# M46B register map
File version: 2.0.2.2
Registers are 32-bit, read-write, reset 0x0 unless marked. A register's access mark holds for its fields unless they carry their own. Offsets are from the block's base; [hi:lo] are bit positions; {n}, {i} and the like mark numbered series.

## MLA — Multiple Length Arithmetic Coprocessor (MLA)
Base 0x400B9000
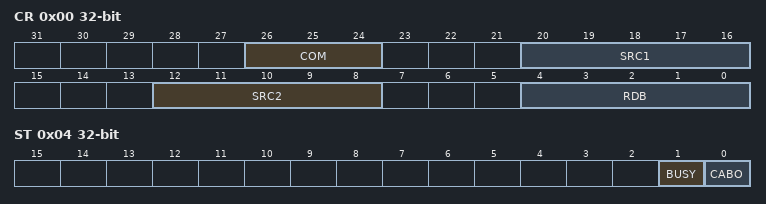
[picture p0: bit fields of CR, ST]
0x00 CR reset not defined — Control Register
  [26:24] COM, [20:16] SRC1, [12:8] SRC2, [4:0] RDB
0x04 ST — Status Register
  [1] BUSY, [0] CABO
0x0C PARA reset not defined — Montgomery Parameter Register
{0x10+4i} BLK1_{i} reset not defined (i=0..7) — General-purpose Register Block 1 (bit {32i+31} - {32i})
  [31:0] BLK
{0x30+4i} BLK2_{i} reset not defined (i=0..7) — General-purpose Register Block 2 (bit {32i+31} - {32i})
  [31:0] BLK
{0x50+4i} BLK3_{i} reset not defined (i=0..7) — General-purpose Register Block 3 (bit {32i+31} - {32i})
  [31:0] BLK
{0x70+4i} BLK4_{i} reset not defined (i=0..7) — General-purpose Register Block 4 (bit {32i+31} - {32i})
  [31:0] BLK
{0x90+4i} BLK5_{i} reset not defined (i=0..7) — General-purpose Register Block 5 (bit {32i+31} - {32i})
  [31:0] BLK
{0xB0+4i} BLK6_{i} reset not defined (i=0..7) — General-purpose Register Block 6 (bit {32i+31} - {32i})
  [31:0] BLK
{0xD0+4i} BLK7_{i} reset not defined (i=0..7) — General-purpose Register Block 7 (bit {32i+31} - {32i})
  [31:0] BLK
{0xF0+4i} BLK8_{i} reset not defined (i=0..7) — General-purpose Register Block 8 (bit {32i+31} - {32i})
  [31:0] BLK
{0x110+4i} BLK9_{i} reset not defined (i=0..7) — General-purpose Register Block 9 (bit {32i+31} - {32i})
  [31:0] BLK
{0x130+4i} BLK10_{i} reset not defined (i=0..7) — General-purpose Register Block 10 (bit {32i+31} - {32i})
  [31:0] BLK
{0x150+4i} BLK11_{i} reset not defined (i=0..7) — General-purpose Register Block 11 (bit {32i+31} - {32i})
  [31:0] BLK
{0x170+4i} BLK12_{i} reset not defined (i=0..7) — General-purpose Register Block 12 (bit {32i+31} - {32i})
  [31:0] BLK
{0x190+4i} BLK13_{i} reset not defined (i=0..7) — General-purpose Register Block 13 (bit {32i+31} - {32i})
  [31:0] BLK
{0x1B0+4i} BLK14_{i} reset not defined (i=0..7) — General-purpose Register Block 14 (bit {32i+31} - {32i})
  [31:0] BLK
{0x1D0+4i} BLK15_{i} reset not defined (i=0..7) — General-purpose Register Block 15 (bit {32i+31} - {32i})
  [31:0] BLK
{0x1F0+4i} BLK16_{i} reset not defined (i=0..7) — General-purpose Register Block 16 (bit {32i+31} - {32i})
  [31:0] BLK
{0x210+4i} BLK17_{i} reset not defined (i=0..7) — General-purpose Register Block 17 (bit {32i+31} - {32i})
  [31:0] BLK
{0x230+4i} BLK18_{i} reset not defined (i=0..7) — General-purpose Register Block 18 (bit {32i+31} - {32i})
  [31:0] BLK
{0x250+4i} BLK19_{i} reset not defined (i=0..7) — General-purpose Register Block 19 (bit {32i+31} - {32i})
  [31:0] BLK
{0x270+4i} BLK20_{i} reset not defined (i=0..7) — General-purpose Register Block 20 (bit {32i+31} - {32i})
  [31:0] BLK
{0x290+4i} BLK21_{i} reset not defined (i=0..7) — General-purpose Register Block 21 (bit {32i+31} - {32i})
  [31:0] BLK
{0x2B0+4i} BLK22_{i} reset not defined (i=0..7) — General-purpose Register Block 22 (bit {32i+31} - {32i})
  [31:0] BLK
{0x2D0+4i} BLK23_{i} reset not defined (i=0..7) — General-purpose Register Block 23 (bit {32i+31} - {32i})
  [31:0] BLK
{0x2F0+4i} BLK24_{i} reset not defined (i=0..7) — General-purpose Register Block 24 (bit {32i+31} - {32i})
  [31:0] BLK
{0x310+4i} BLK25_{i} reset not defined (i=0..7) — General-purpose Register Block 25 (bit {32i+31} - {32i})
  [31:0] BLK
{0x330+4i} BLK26_{i} reset not defined (i=0..7) — General-purpose Register Block 26 (bit {32i+31} - {32i})
  [31:0] BLK
{0x350+4i} BLK27_{i} reset not defined (i=0..7) — General-purpose Register Block 27 (bit {32i+31} - {32i})
  [31:0] BLK
{0x370+4i} BLK28_{i} reset not defined (i=0..7) — General-purpose Register Block 28 (bit {32i+31} - {32i})
  [31:0] BLK
{0x390+4i} BLK29_{i} reset not defined (i=0..7) — General-purpose Register Block 29 (bit {32i+31} - {32i})
  [31:0] BLK
{0x3B0+4i} BLK30_{i} reset not defined (i=0..7) — General-purpose Register Block 30 (bit {32i+31} - {32i})
  [31:0] BLK
{0x3D0+4i} BLK31_{i} reset not defined (i=0..7) — General-purpose Register Block 31 (bit {32i+31} - {32i})
  [31:0] BLK
{0x800+4i} BLK0_{i} reset not defined (i=0..7) — General-purpose Register Block 0 (bit {32i+31} - {32i})
  [31:0] BLK
